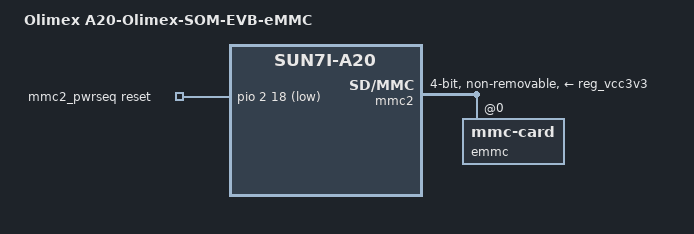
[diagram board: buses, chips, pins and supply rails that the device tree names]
// SPDX-License-Identifier: (GPL-2.0+ OR MIT)
/*
 * Device Tree Source for A20-Olimex-SOM-EVB-eMMC Board
 *
 * Copyright (C) 2018 Olimex Ltd.
 *   Author: Stefan Mavrodiev <stefan@olimex.com>
 */

/dts-v1/;
#include "sun7i-a20-olimex-som-evb.dts"

/ {

	model = "Olimex A20-Olimex-SOM-EVB-eMMC";
	compatible = "olimex,a20-olimex-som-evb-emmc", "allwinner,sun7i-a20";

	mmc2_pwrseq: mmc2_pwrseq {
		compatible = "mmc-pwrseq-emmc";
		reset-gpios = <&pio 2 18 GPIO_ACTIVE_LOW>;
	};
};

&mmc2 {
	pinctrl-names = "default";
	pinctrl-0 = <&mmc2_pins_a>;
	vmmc-supply = <&reg_vcc3v3>;
	mmc-pwrseq = <&mmc2_pwrseq>;
	bus-width = <4>;
	non-removable;
	status = "okay";

	emmc: emmc@0 {
		reg = <0>;
		compatible = "mmc-card";
		broken-hpi;
	};
};
